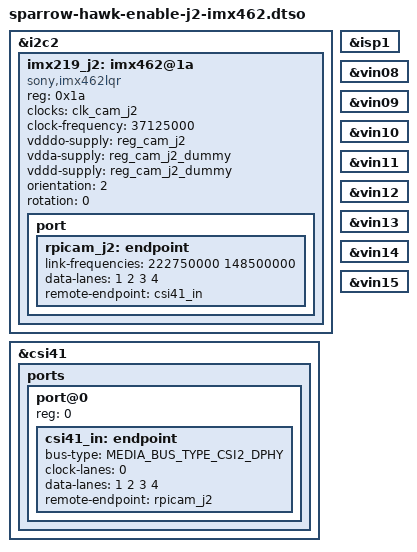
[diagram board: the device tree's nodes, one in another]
/dts-v1/;
/plugin/;

#include <dt-bindings/media/video-interfaces.h>

/* Page 29 / CSI_IF_CN / CAM_CN1 */
&i2c2 {
	status = "okay";

	imx219_j2: imx462@1a {
		compatible = "sony,imx462lqr";
		reg = <0x1a>;
		status = "okay";

		clocks = <&clk_cam_j2>;
		clock-names = "xclk";
		clock-frequency = <37125000>;

		vdddo-supply = <&reg_cam_j2>;
		vdda-supply = <&reg_cam_j2_dummy>;
		vddd-supply = <&reg_cam_j2_dummy>;

		orientation = <2>;
		rotation = <0>;

		port {
			rpicam_j2: endpoint {
				link-frequencies = /bits/ 64 <222750000 148500000>;
				data-lanes = <1 2 3 4>;
				remote-endpoint = <&csi41_in>;
			};
		};
	};
};

/* Page 29 / CSI_IF_CN */
&csi41 {
	status = "okay";

	ports {
		#address-cells = <1>;
		#size-cells = <0>;

		port@0 {
			reg = <0>;

			csi41_in: endpoint {
				bus-type = <MEDIA_BUS_TYPE_CSI2_DPHY>;
				clock-lanes = <0>;
				data-lanes = <1 2 3 4>;
				remote-endpoint = <&rpicam_j2>;
			};
		};
	};
};
&isp1 {
	status = "okay";
};

&vin08 {
	status = "okay";
};

&vin09 {
	status = "okay";
};

&vin10 {
	status = "okay";
};

&vin11 {
	status = "okay";
};

&vin12 {
	status = "okay";
};

&vin13 {
	status = "okay";
};

&vin14 {
	status = "okay";
};

&vin15 {
	status = "okay";
};
